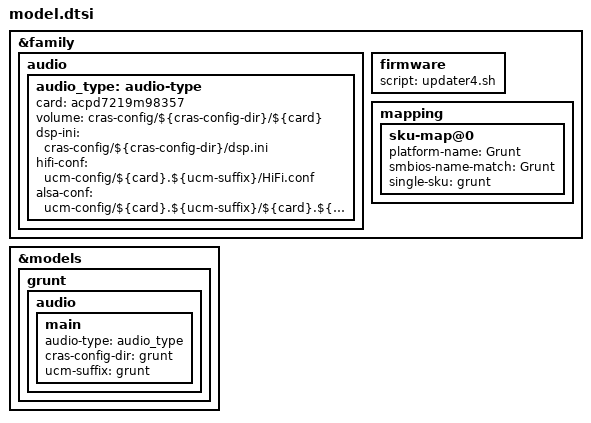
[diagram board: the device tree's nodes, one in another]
/*
 * Copyright 2018 The Chromium OS Authors. All rights reserved.
 *
 * Use of this source code is governed by a BSD-style license that can be
 * found in the LICENSE file.
 */

&family {
	audio {
		audio_type: audio-type {
			card = "acpd7219m98357";
			volume = "cras-config/${cras-config-dir}/${card}";
			dsp-ini = "cras-config/${cras-config-dir}/dsp.ini";
			hifi-conf = "ucm-config/${card}.${ucm-suffix}/HiFi.conf";
			alsa-conf = "ucm-config/${card}.${ucm-suffix}/${card}.${ucm-suffix}.conf";
		};
	};

	firmware {
		script = "updater4.sh";
	};

	mapping {
		sku-map@0 {
			platform-name = "Grunt";
			smbios-name-match = "Grunt";
			single-sku = <&grunt>;
		};
	};
};

&models {
	grunt: grunt {
		audio {
			main {
				audio-type = <&audio_type>;
				cras-config-dir = "grunt";
				ucm-suffix = "grunt";
			};
		};
	};
};
